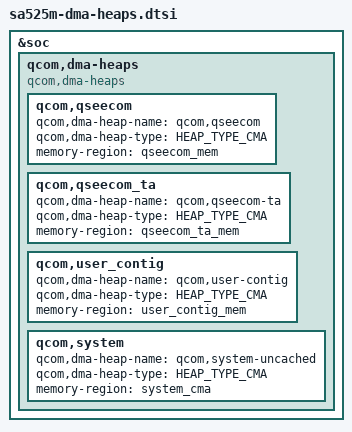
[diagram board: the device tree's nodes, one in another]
&soc {
	qcom,dma-heaps {
		compatible = "qcom,dma-heaps";

		qcom,qseecom {
			qcom,dma-heap-name = "qcom,qseecom";
			qcom,dma-heap-type = <HEAP_TYPE_CMA>;
			memory-region = <&qseecom_mem>;
		};

		qcom,qseecom_ta {
			qcom,dma-heap-name = "qcom,qseecom-ta";
			qcom,dma-heap-type = <HEAP_TYPE_CMA>;
			memory-region = <&qseecom_ta_mem>;
		};

		qcom,user_contig {
			qcom,dma-heap-name = "qcom,user-contig";
			qcom,dma-heap-type = <HEAP_TYPE_CMA>;
			memory-region = <&user_contig_mem>;
		};

		qcom,system {
			qcom,dma-heap-name = "qcom,system-uncached";
			qcom,dma-heap-type = <HEAP_TYPE_CMA>;
			memory-region = <&system_cma>;
		};
	};
};
